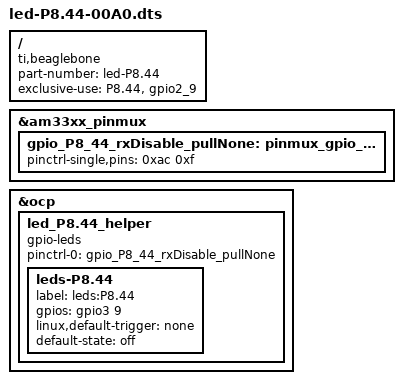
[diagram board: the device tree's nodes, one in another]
/*
* Easy gpio mux control of "P8.44" ("gpio2_9")
*/
/dts-v1/;
/plugin/;

/ {
	compatible = "ti,beaglebone", "ti,beaglebone-black";

	/* identification */
	part-number = "led-P8.44";
	/* version = "00A0"; */

	/* state the resources this cape uses */
	exclusive-use =
		/* the pin header uses */
		"P8.44",

		/* the hardware IP uses */
		"gpio2_9";
	
	
	/* rxDisable_pullNone state */
	fragment@0 {
		target = <&am33xx_pinmux>;
		__overlay__ {
			gpio_P8_44_rxDisable_pullNone: pinmux_gpio_P8.44_rxDisable_pullNone {
				pinctrl-single,pins = <
					0xac 0xf
				>;
			};
		};
	};

	fragment@1 {
		target = <&ocp>;
		__overlay__ {
			led_P8.44_helper {
				compatible = "gpio-leds";
				pinctrl-names = "default";
				pinctrl-0 = <&gpio_P8_44_rxDisable_pullNone>;
				
				leds-P8.44 {
					label = "leds:P8.44";
					gpios = <&gpio3 9 0>;
					linux,default-trigger = "none";
					default-state = "off";
				};
			};
			
		};
	};

};
